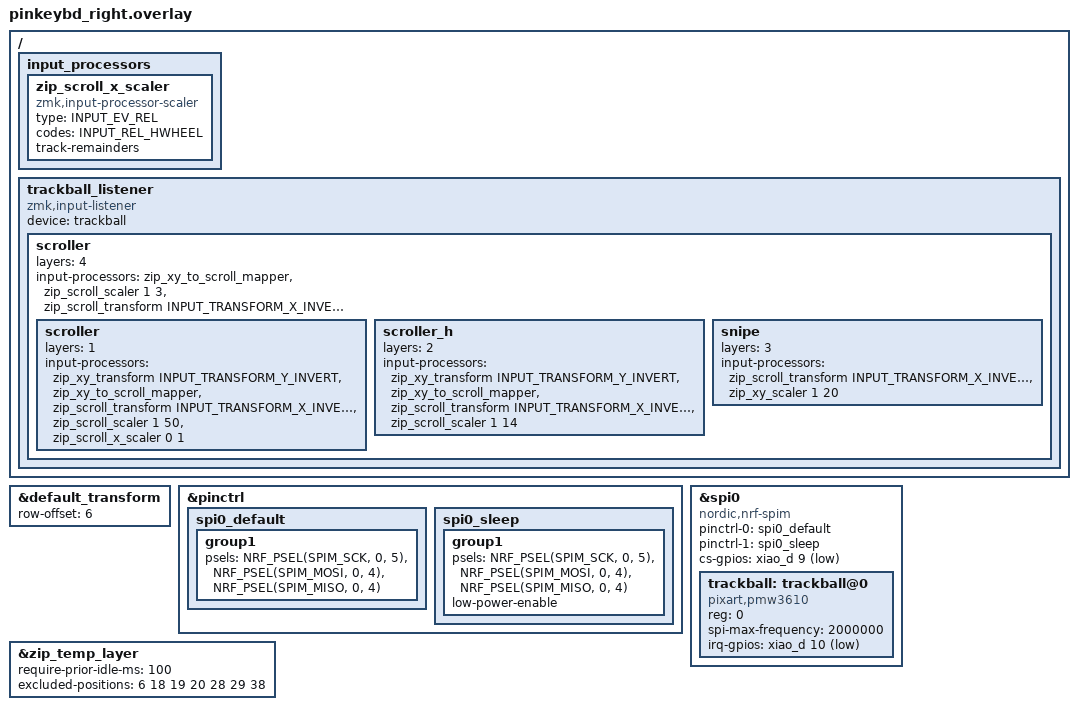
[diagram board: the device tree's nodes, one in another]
#include "pinkeybd.dtsi"
#include <dt-bindings/zmk/matrix_transform.h>
#include <physical_layouts.dtsi>
#include <dt-bindings/input/input-event-codes.h>
#include <zephyr/dt-bindings/input/input-event-codes.h>
#include <input/processors.dtsi>
#include <dt-bindings/zmk/input_transform.h>



/ {
    input_processors {
        zip_scroll_x_scaler: zip_scroll_x_scaler {
            compatible = "zmk,input-processor-scaler";
            #input-processor-cells = <2>;
            type = <INPUT_EV_REL>;
            codes = <INPUT_REL_HWHEEL>;
            track-remainders;
        };
    };
};


// The matrix transform for this board is 6 columns over because the left half is 5 columns wide according to the matrix.
&default_transform {
    row-offset = <6>;
};

&pinctrl {
    spi0_default: spi0_default {
        group1 {
            psels = <NRF_PSEL(SPIM_SCK, 0, 5)>, //SCLK
                    <NRF_PSEL(SPIM_MOSI, 0, 4)>, //SDIO
                    <NRF_PSEL(SPIM_MISO, 0, 4)>; //SDIO
        };
    };

    spi0_sleep: spi0_sleep {
        group1 {
            psels = <NRF_PSEL(SPIM_SCK, 0, 5)>, //SCLK
                    <NRF_PSEL(SPIM_MOSI, 0, 4)>, //SDIO
                    <NRF_PSEL(SPIM_MISO, 0, 4)>; //SDIO
            low-power-enable;
        };
    };
};

&spi0 {
    status = "okay";
    compatible = "nordic,nrf-spim";
    pinctrl-0 = <&spi0_default>;
    pinctrl-1 = <&spi0_sleep>;
    pinctrl-names = "default", "sleep";
    cs-gpios = <&xiao_d 9 GPIO_ACTIVE_LOW>; //NCS

    trackball: trackball@0 {
        status = "okay";
        compatible = "pixart,pmw3610";
        reg = <0>;
        spi-max-frequency = <2000000>;
        irq-gpios = <&xiao_d 10 (GPIO_ACTIVE_LOW | GPIO_PULL_UP)>; //MOT
        //cpi = <600>;
        //evt-type = <INPUT_EV_REL>;
        //x-input-code = <INPUT_REL_X>;
        //y-input-code = <INPUT_REL_Y>;
        //automouse-layer = <5>;
    };
};

&zip_temp_layer {
    require-prior-idle-ms = <100>;
};

&zip_temp_layer {
    excluded-positions = <
        6
        18
        19
        20
        28
        29
        38
    >;
};

/ {
    trackball_listener: trackball_listener {
        status = "okay";
        compatible = "zmk,input-listener";
        device = <&trackball>;

//        input-processors = <&zip_temp_layer 5 2000>;

        scroller {
            layers = <4>;
            input-processors = <
                &zip_xy_to_scroll_mapper
                &zip_scroll_scaler 1 3
                &zip_scroll_transform INPUT_TRANSFORM_X_INVERT
            >;

  scroller {
        layers = <1>;
        input-processors = 
            // <&zip_xy_transform INPUT_TRANSFORM_XY_SWAP>,        //X軸とY軸の入れ替え
            // <&zip_xy_transform INPUT_TRANSFORM_X_INVERT>,       //X軸反転
            <&zip_xy_transform INPUT_TRANSFORM_Y_INVERT>,       //Y軸反転
            <&zip_xy_to_scroll_mapper>,                         //スクロールモードに変更
            <&zip_scroll_transform INPUT_TRANSFORM_X_INVERT>,   //スクロールのX軸反転
            //<&zip_scroll_transform INPUT_TRANSFORM_Y_INVERT>,   //スクロールのY軸反転
            <&zip_scroll_scaler 1 50>,                           //スクロール量を1/14倍
            <&zip_scroll_x_scaler 0 1>;
    };

    scroller_h {
        layers = <2>;
        input-processors = 
            // <&zip_xy_transform INPUT_TRANSFORM_XY_SWAP>,        //X軸とY軸の入れ替え
            // <&zip_xy_transform INPUT_TRANSFORM_X_INVERT>,       //X軸反転
            <&zip_xy_transform INPUT_TRANSFORM_Y_INVERT>,       //Y軸反転
            <&zip_xy_to_scroll_mapper>,                         //スクロールモードに変更
            <&zip_scroll_transform INPUT_TRANSFORM_X_INVERT>,   //スクロールのX軸反転
            //<&zip_scroll_transform INPUT_TRANSFORM_Y_INVERT>,   //スクロールのY軸反転
            <&zip_scroll_scaler 1 14>;                           //スクロール量を1/8倍
    };


    snipe {
        layers = <3>;
        input-processors = 
            
            <&zip_scroll_transform INPUT_TRANSFORM_X_INVERT>,   //スクロールのX軸反転
            
            <&zip_xy_scaler 1 20>;                           //スクロール量を1/8倍
    };


        };
    };
};
